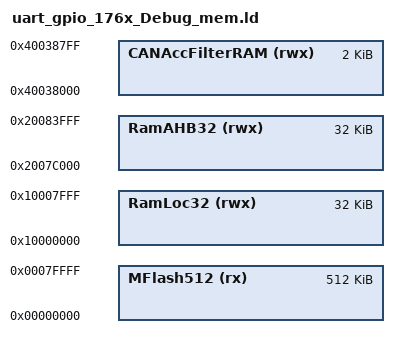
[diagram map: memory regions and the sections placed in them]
/*
 * GENERATED FILE - DO NOT EDIT
 * (C) Code Red Technologies Ltd, 2008-2013
 * Linker script memory definitions
 * Created from LinkMemoryTemplate
 * By LPCXpresso v5.2.4 [Build 2122] [2013-04-29]  on Tue Jul 23 01:15:02 JST 2013)
*/

MEMORY
{
  /* Define each memory region */
  MFlash512 (rx) : ORIGIN = 0x0, LENGTH = 0x80000 /* 512k */
  RamLoc32 (rwx) : ORIGIN = 0x10000000, LENGTH = 0x8000 /* 32k */
  RamAHB32 (rwx) : ORIGIN = 0x2007c000, LENGTH = 0x8000 /* 32k */
  CANAccFilterRAM (rwx) : ORIGIN = 0x40038000, LENGTH = 0x800 /* 2k */

}
  /* Define a symbol for the top of each memory region */
  __top_MFlash512 = 0x0 + 0x80000;
  __top_RamLoc32 = 0x10000000 + 0x8000;
  __top_RamAHB32 = 0x2007c000 + 0x8000;
  __top_CANAccFilterRAM = 0x40038000 + 0x800;

